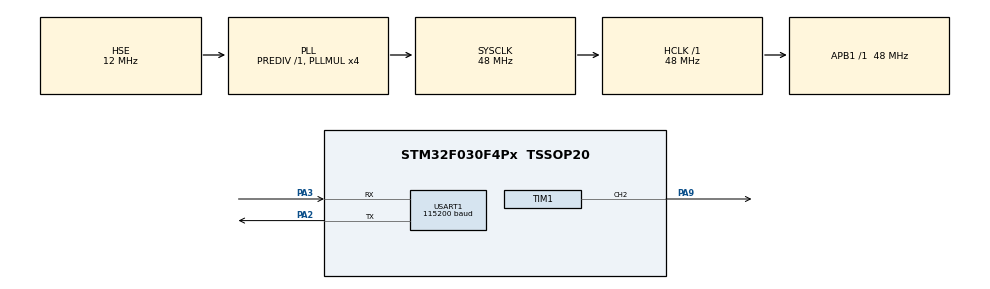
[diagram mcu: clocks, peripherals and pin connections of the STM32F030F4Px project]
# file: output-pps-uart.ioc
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ADC.LowPowerAutoWait=ENABLE
ADC.SamplingTime=ADC_SAMPLETIME_239CYCLES_5
Mcu.Family=STM32F0
Mcu.Name=STM32F030F4Px
Mcu.Package=TSSOP20
NVIC.TIM3_IRQn=true\:0\:0\:false\:false\:true\:true
NVIC.USART1_IRQn=true\:3\:0\:true\:false\:true\:true
PA13.Mode=Serial_Wire
PA13.Signal=SYS_SWDIO
PA14.Mode=Serial_Wire
PA14.Signal=SYS_SWCLK
PA2.Mode=Asynchronous
PA2.Signal=USART1_TX
PA3.Mode=Asynchronous
PA3.Signal=USART1_RX
PA9.Signal=S_TIM1_CH2
PF0-OSC_IN.Mode=HSE-External-Clock-Source
PF0-OSC_IN.Signal=RCC_OSC_IN
ProjectManager.HeapSize=0x200
ProjectManager.StackSize=0x400
ProjectManager.TargetToolchain=Makefile
RCC.AHBFreq_Value=48000000
RCC.APB1Freq_Value=48000000
RCC.APB1TimFreq_Value=48000000
RCC.HCLKFreq_Value=48000000
RCC.HSE_VALUE=12000000
RCC.PLLMUL=RCC_PLL_MUL4
RCC.PLLSourceVirtual=RCC_PLLSOURCE_HSE
RCC.SYSCLKFreq_VALUE=48000000
RCC.SYSCLKSource=RCC_SYSCLKSOURCE_PLLCLK
SH.S_TIM1_CH2.0=TIM1_CH2,PWM Generation2 CH2
TIM1.Channel-PWM\ Generation2\ CH2=TIM_CHANNEL_2
TIM1.Period=999
TIM1.Prescaler=0
TIM1.Pulse-PWM\ Generation2\ CH2=1
TIM3.Period=47999
TIM3.Prescaler=0
TIM3.TIM_MasterOutputTrigger=TIM_TRGO_UPDATE
TIM3.TIM_MasterSlaveMode=TIM_MASTERSLAVEMODE_ENABLE
USART1.BaudRate=115200
USART1.VirtualMode-Asynchronous=VM_ASYNC
VP_ADC_TempSens_Input.Mode=IN-TempSens
VP_ADC_Vref_Input.Mode=IN-Vrefint
VP_TIM1_VS_ClockSourceITR.Mode=TriggerSource_ITR2
VP_TIM1_VS_ControllerModeClock.Mode=Clock Mode
VP_TIM3_VS_ClockSourceINT.Mode=Internal
board=output-pps-uart

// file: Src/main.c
/**
  ******************************************************************************
  * File Name          : main.c
  * Description        : Main program body
  ******************************************************************************
  ** This notice applies to any and all portions of this file
  * that are not between comment pairs USER CODE BEGIN and
  * USER CODE END. Other portions of this file, whether
  * inserted by the user or by software development tools
  * are owned by their respective copyright owners.
  *
  * COPYRIGHT(c) 2018 STMicroelectronics
  *
  * Redistribution and use in source and binary forms, with or without modification,
  * are permitted provided that the following conditions are met:
  *   1. Redistributions of source code must retain the above copyright notice,
  *      this list of conditions and the following disclaimer.
  *   2. Redistributions in binary form must reproduce the above copyright notice,
  *      this list of conditions and the following disclaimer in the documentation
  *      and/or other materials provided with the distribution.
  *   3. Neither the name of STMicroelectronics nor the names of its contributors
  *      may be used to endorse or promote products derived from this software
  *      without specific prior written permission.
  *
  * THIS SOFTWARE IS PROVIDED BY THE COPYRIGHT HOLDERS AND CONTRIBUTORS "AS IS"
  * AND ANY EXPRESS OR IMPLIED WARRANTIES, INCLUDING, BUT NOT LIMITED TO, THE
  * IMPLIED WARRANTIES OF MERCHANTABILITY AND FITNESS FOR A PARTICULAR PURPOSE ARE
  * DISCLAIMED. IN NO EVENT SHALL THE COPYRIGHT HOLDER OR CONTRIBUTORS BE LIABLE
  * FOR ANY DIRECT, INDIRECT, INCIDENTAL, SPECIAL, EXEMPLARY, OR CONSEQUENTIAL
  * DAMAGES (INCLUDING, BUT NOT LIMITED TO, PROCUREMENT OF SUBSTITUTE GOODS OR
  * SERVICES; LOSS OF USE, DATA, OR PROFITS; OR BUSINESS INTERRUPTION) HOWEVER
  * CAUSED AND ON ANY THEORY OF LIABILITY, WHETHER IN CONTRACT, STRICT LIABILITY,
  * OR TORT (INCLUDING NEGLIGENCE OR OTHERWISE) ARISING IN ANY WAY OUT OF THE USE
  * OF THIS SOFTWARE, EVEN IF ADVISED OF THE POSSIBILITY OF SUCH DAMAGE.
  *
  ******************************************************************************
  */

#include "main.h"
#include "stm32f0xx_hal.h"

/* USER CODE BEGIN Includes */
#include "uart.h"
#include "adc.h"
#include "commandline.h"
#include "timer.h"
/* USER CODE END Includes */

ADC_HandleTypeDef hadc;

TIM_HandleTypeDef htim1;
TIM_HandleTypeDef htim3;

UART_HandleTypeDef huart1;

/* USER CODE BEGIN PV */
/* Private variables ---------------------------------------------------------*/

/* USER CODE END PV */

void SystemClock_Config(void);
static void MX_GPIO_Init(void);
static void MX_USART1_UART_Init(void);
static void MX_TIM1_Init(void);
static void MX_ADC_Init(void);
static void MX_TIM3_Init(void);

void HAL_TIM_MspPostInit(TIM_HandleTypeDef *htim);

/* USER CODE BEGIN PFP */
/* Private function prototypes -----------------------------------------------*/

/* USER CODE END PFP */

int main(void)
{

  /* MCU Configuration----------------------------------------------------------*/

  /* Reset of all peripherals, Initializes the Flash interface and the Systick. */
  HAL_Init();

  /* Configure the system clock */
  SystemClock_Config();

  /* Initialize all configured peripherals */
  MX_GPIO_Init();
  MX_USART1_UART_Init();
  MX_TIM1_Init();
  MX_ADC_Init();
  MX_TIM3_Init();

  /* USER CODE BEGIN 2 */
  HAL_ADCEx_Calibration_Start(&hadc);
  start_rx_uart();
  timer_start();
  write_uart_s("pwm output starting\n");
  cmdline_prompt();
  /* USER CODE END 2 */

  /* Infinite loop */
  while (1)
  {

  /* USER CODE BEGIN 3 */
    uint16_t next_adc = 50; // start at 50ms
    while(1) {
      while(__HAL_TIM_GET_COUNTER(&htim1) < next_adc) {
        while(uart_rx_ready()) {
          cmdline_addchr(uart_rx_data());
        }
      }
      adc_poll();
      next_adc += 100; // every 100ms
      if(next_adc > 1000) {
        break;
      }
    }
    // happens after 950ms
    update_adc();

    adjust_pps();

    // wait till wrap to 0ms
    while(__HAL_TIM_GET_COUNTER(&htim1) >= 950) {
      while(uart_rx_ready()) {
        cmdline_addchr(uart_rx_data());
      }
    }
  }
  /* USER CODE END 3 */

}

/** System Clock Configuration
*/
void SystemClock_Config(void)
{

  RCC_OscInitTypeDef RCC_OscInitStruct;
  RCC_ClkInitTypeDef RCC_ClkInitStruct;
  RCC_PeriphCLKInitTypeDef PeriphClkInit;

    /**Initializes the CPU, AHB and APB busses clocks
    */
  RCC_OscInitStruct.OscillatorType = RCC_OSCILLATORTYPE_HSI14|RCC_OSCILLATORTYPE_HSE;
  RCC_OscInitStruct.HSEState = RCC_HSE_BYPASS;
  RCC_OscInitStruct.HSI14State = RCC_HSI14_ON;
  RCC_OscInitStruct.HSI14CalibrationValue = 16;
  RCC_OscInitStruct.PLL.PLLState = RCC_PLL_ON;
  RCC_OscInitStruct.PLL.PLLSource = RCC_PLLSOURCE_HSE;
  RCC_OscInitStruct.PLL.PLLMUL = RCC_PLL_MUL4;
  RCC_OscInitStruct.PLL.PREDIV = RCC_PREDIV_DIV1;
  if (HAL_RCC_OscConfig(&RCC_OscInitStruct) != HAL_OK)
  {
    _Error_Handler(__FILE__, __LINE__);
  }

    /**Initializes the CPU, AHB and APB busses clocks
    */
  RCC_ClkInitStruct.ClockType = RCC_CLOCKTYPE_HCLK|RCC_CLOCKTYPE_SYSCLK
                              |RCC_CLOCKTYPE_PCLK1;
  RCC_ClkInitStruct.SYSCLKSource = RCC_SYSCLKSOURCE_PLLCLK;
  RCC_ClkInitStruct.AHBCLKDivider = RCC_SYSCLK_DIV1;
  RCC_ClkInitStruct.APB1CLKDivider = RCC_HCLK_DIV1;

  if (HAL_RCC_ClockConfig(&RCC_ClkInitStruct, FLASH_LATENCY_1) != HAL_OK)
  {
    _Error_Handler(__FILE__, __LINE__);
  }

  PeriphClkInit.PeriphClockSelection = RCC_PERIPHCLK_USART1;
  PeriphClkInit.Usart1ClockSelection = RCC_USART1CLKSOURCE_PCLK1;
  if (HAL_RCCEx_PeriphCLKConfig(&PeriphClkInit) != HAL_OK)
  {
    _Error_Handler(__FILE__, __LINE__);
  }

    /**Configure the Systick interrupt time
    */
  HAL_SYSTICK_Config(HAL_RCC_GetHCLKFreq()/1000);

    /**Configure the Systick
    */
  HAL_SYSTICK_CLKSourceConfig(SYSTICK_CLKSOURCE_HCLK);

  /* SysTick_IRQn interrupt configuration */
  HAL_NVIC_SetPriority(SysTick_IRQn, 0, 0);
}

/* ADC init function */
static void MX_ADC_Init(void)
{

  ADC_ChannelConfTypeDef sConfig;

    /**Configure the global features of the ADC (Clock, Resolution, Data Alignment and number of conversion)
    */
  hadc.Instance = ADC1;
  hadc.Init.ClockPrescaler = ADC_CLOCK_ASYNC_DIV1;
  hadc.Init.Resolution = ADC_RESOLUTION_12B;
  hadc.Init.DataAlign = ADC_DATAALIGN_RIGHT;
  hadc.Init.ScanConvMode = ADC_SCAN_DIRECTION_FORWARD;
  hadc.Init.EOCSelection = ADC_EOC_SINGLE_CONV;
  hadc.Init.LowPowerAutoWait = ENABLE;
  hadc.Init.LowPowerAutoPowerOff = DISABLE;
  hadc.Init.ContinuousConvMode = DISABLE;
  hadc.Init.DiscontinuousConvMode = DISABLE;
  hadc.Init.ExternalTrigConv = ADC_SOFTWARE_START;
  hadc.Init.ExternalTrigConvEdge = ADC_EXTERNALTRIGCONVEDGE_NONE;
  hadc.Init.DMAContinuousRequests = DISABLE;
  hadc.Init.Overrun = ADC_OVR_DATA_PRESERVED;
  if (HAL_ADC_Init(&hadc) != HAL_OK)
  {
    _Error_Handler(__FILE__, __LINE__);
  }

    /**Configure for the selected ADC regular channel to be converted.
    */
  sConfig.Channel = ADC_CHANNEL_TEMPSENSOR;
  sConfig.Rank = ADC_RANK_CHANNEL_NUMBER;
  sConfig.SamplingTime = ADC_SAMPLETIME_239CYCLES_5;
  if (HAL_ADC_ConfigChannel(&hadc, &sConfig) != HAL_OK)
  {
    _Error_Handler(__FILE__, __LINE__);
  }

    /**Configure for the selected ADC regular channel to be converted.
    */
  sConfig.Channel = ADC_CHANNEL_VREFINT;
  if (HAL_ADC_ConfigChannel(&hadc, &sConfig) != HAL_OK)
  {
    _Error_Handler(__FILE__, __LINE__);
  }

}

/* TIM1 init function */
static void MX_TIM1_Init(void)
{

  TIM_SlaveConfigTypeDef sSlaveConfig;
  TIM_MasterConfigTypeDef sMasterConfig;
  TIM_OC_InitTypeDef sConfigOC;
  TIM_BreakDeadTimeConfigTypeDef sBreakDeadTimeConfig;

  htim1.Instance = TIM1;
  htim1.Init.Prescaler = 0;
  htim1.Init.CounterMode = TIM_COUNTERMODE_UP;
  htim1.Init.Period = 999;
  htim1.Init.ClockDivision = TIM_CLOCKDIVISION_DIV1;
  htim1.Init.RepetitionCounter = 0;
  htim1.Init.AutoReloadPreload = TIM_AUTORELOAD_PRELOAD_DISABLE;
  if (HAL_TIM_Base_Init(&htim1) != HAL_OK)
  {
    _Error_Handler(__FILE__, __LINE__);
  }

  if (HAL_TIM_PWM_Init(&htim1) != HAL_OK)
  {
    _Error_Handler(__FILE__, __LINE__);
  }

  sSlaveConfig.SlaveMode = TIM_SLAVEMODE_EXTERNAL1;
  sSlaveConfig.InputTrigger = TIM_TS_ITR2;
  if (HAL_TIM_SlaveConfigSynchronization(&htim1, &sSlaveConfig) != HAL_OK)
  {
    _Error_Handler(__FILE__, __LINE__);
  }

  sMasterConfig.MasterOutputTrigger = TIM_TRGO_RESET;
  sMasterConfig.MasterSlaveMode = TIM_MASTERSLAVEMODE_DISABLE;
  if (HAL_TIMEx_MasterConfigSynchronization(&htim1, &sMasterConfig) != HAL_OK)
  {
    _Error_Handler(__FILE__, __LINE__);
  }

  sConfigOC.OCMode = TIM_OCMODE_PWM1;
  sConfigOC.Pulse = 1;
  sConfigOC.OCPolarity = TIM_OCPOLARITY_HIGH;
  sConfigOC.OCNPolarity = TIM_OCNPOLARITY_HIGH;
  sConfigOC.OCFastMode = TIM_OCFAST_DISABLE;
  sConfigOC.OCIdleState = TIM_OCIDLESTATE_RESET;
  sConfigOC.OCNIdleState = TIM_OCNIDLESTATE_RESET;
  if (HAL_TIM_PWM_ConfigChannel(&htim1, &sConfigOC, TIM_CHANNEL_2) != HAL_OK)
  {
    _Error_Handler(__FILE__, __LINE__);
  }

  sBreakDeadTimeConfig.OffStateRunMode = TIM_OSSR_DISABLE;
  sBreakDeadTimeConfig.OffStateIDLEMode = TIM_OSSI_DISABLE;
  sBreakDeadTimeConfig.LockLevel = TIM_LOCKLEVEL_OFF;
  sBreakDeadTimeConfig.DeadTime = 0;
  sBreakDeadTimeConfig.BreakState = TIM_BREAK_DISABLE;
  sBreakDeadTimeConfig.BreakPolarity = TIM_BREAKPOLARITY_HIGH;
  sBreakDeadTimeConfig.AutomaticOutput = TIM_AUTOMATICOUTPUT_DISABLE;
  if (HAL_TIMEx_ConfigBreakDeadTime(&htim1, &sBreakDeadTimeConfig) != HAL_OK)
  {
    _Error_Handler(__FILE__, __LINE__);
  }

  HAL_TIM_MspPostInit(&htim1);

}

/* TIM3 init function */
static void MX_TIM3_Init(void)
{

  TIM_ClockConfigTypeDef sClockSourceConfig;
  TIM_MasterConfigTypeDef sMasterConfig;

  htim3.Instance = TIM3;
  htim3.Init.Prescaler = 0;
  htim3.Init.CounterMode = TIM_COUNTERMODE_UP;
  htim3.Init.Period = 47999;
  htim3.Init.ClockDivision = TIM_CLOCKDIVISION_DIV1;
  htim3.Init.AutoReloadPreload = TIM_AUTORELOAD_PRELOAD_DISABLE;
  if (HAL_TIM_Base_Init(&htim3) != HAL_OK)
  {
    _Error_Handler(__FILE__, __LINE__);
  }

  sClockSourceConfig.ClockSource = TIM_CLOCKSOURCE_INTERNAL;
  if (HAL_TIM_ConfigClockSource(&htim3, &sClockSourceConfig) != HAL_OK)
  {
    _Error_Handler(__FILE__, __LINE__);
  }

  sMasterConfig.MasterOutputTrigger = TIM_TRGO_UPDATE;
  sMasterConfig.MasterSlaveMode = TIM_MASTERSLAVEMODE_ENABLE;
  if (HAL_TIMEx_MasterConfigSynchronization(&htim3, &sMasterConfig) != HAL_OK)
  {
    _Error_Handler(__FILE__, __LINE__);
  }

}

/* USART1 init function */
static void MX_USART1_UART_Init(void)
{

  huart1.Instance = USART1;
  huart1.Init.BaudRate = 115200;
  huart1.Init.WordLength = UART_WORDLENGTH_8B;
  huart1.Init.StopBits = UART_STOPBITS_1;
  huart1.Init.Parity = UART_PARITY_NONE;
  huart1.Init.Mode = UART_MODE_TX_RX;
  huart1.Init.HwFlowCtl = UART_HWCONTROL_NONE;
  huart1.Init.OverSampling = UART_OVERSAMPLING_16;
  huart1.Init.OneBitSampling = UART_ONE_BIT_SAMPLE_DISABLE;
  huart1.AdvancedInit.AdvFeatureInit = UART_ADVFEATURE_NO_INIT;
  if (HAL_UART_Init(&huart1) != HAL_OK)
  {
    _Error_Handler(__FILE__, __LINE__);
  }

}

/** Configure pins as
        * Analog
        * Input
        * Output
        * EVENT_OUT
        * EXTI
*/
static void MX_GPIO_Init(void)
{

  /* GPIO Ports Clock Enable */
  __HAL_RCC_GPIOF_CLK_ENABLE();
  __HAL_RCC_GPIOA_CLK_ENABLE();

}

void _Error_Handler(char * file, int line)
{
  while(1)
  {
  }
}

/************************ (C) COPYRIGHT STMicroelectronics *****END OF FILE****/
